AUTOSAR XML (schema 4-3-0)
package /ComponentTypes
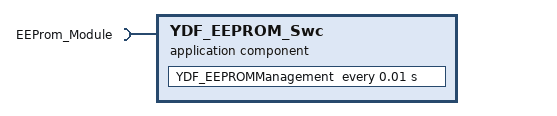
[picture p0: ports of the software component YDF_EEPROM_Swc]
  application sw component type YDF_EEPROM_Swc
    require port EEProm_Module: required-com-specs=[Fee_WriteFunction, Fee_ReadFunction], required-interface=EEProm_Module
    behavior YDF_EEPROM_Swc_InternalBehavior
      timing event TMT_YDF_EEPROMManagement: start-on-event=YDF_EEPROMManagement, period=0.01
      runnable YDF_EEPROMManagement
        sync call SC_EEProm_Module_Fee_ReadFunction: operation=EEProm_Module.Fee_ReadFunction
        sync call SC_EEProm_Module_Fee_WriteFunction: operation=EEProm_Module.Fee_WriteFunction
  swc implementation YDF_EEPROM_Swc_Implementation: behavior=YDF_EEPROM_Swc_InternalBehavior
